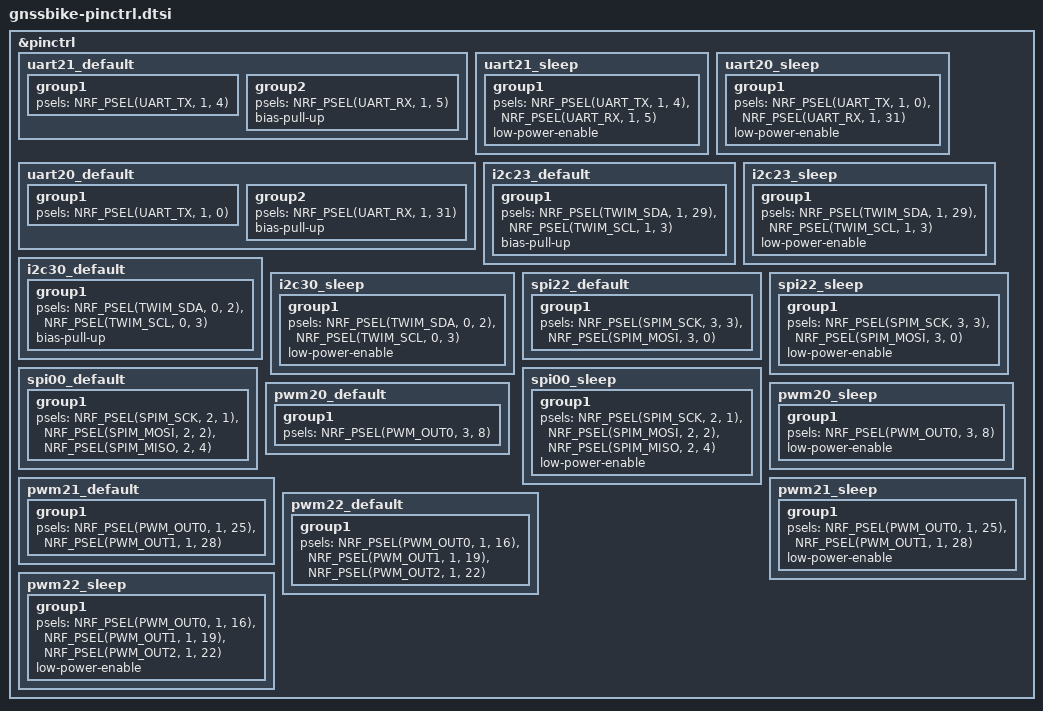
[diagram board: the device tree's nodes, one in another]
/*
 * Pin map of the GNSS Bike Computer board.
 *
 * Two rules of the nRF54LM20A (datasheet 4539_001 v1.0) shape it:
 *
 *   - **Clock pins.** The SCL of a TWIM and the SCK of a SPIM only work on
 *     P0.03, P0.04, P0.06, P0.07, P1.03, P1.04, P1.07, P1.13, P1.14, P1.17,
 *     P1.18, P1.23, P1.24, P2.01, P2.06, P3.03 and P3.04 (table 79). The
 *     data pin of the same peripheral sits on a neighbouring ball so the
 *     internal delays match. Three of the four buses here need one, and
 *     they take P0.03, P1.03, P2.01 and P3.03; the rest are left free so a
 *     revision has somewhere to put another bus.
 *   - **NFC pads.** P1.01 (NFC1) and P1.02 (NFC2) leave reset as antenna
 *     pins with the GPIO function off (table 78, NFCT PADCONFIG). Nothing
 *     here uses them, so an NFC antenna stays possible on a later revision.
 *
 * P1.20 and P1.21 carry the 32,768 kHz crystal and are not available.
 *
 * The serial blocks follow the power domains of the part: `spi00` on port
 * P2, blocks 20 to 24 on P1 and P3, block 30 on P0.
 */

&pinctrl {
	/* ---- GNSS: u-blox MAX-F10S through the TXU0204 level shifter ---- */
	uart21_default: uart21_default {
		group1 {
			psels = <NRF_PSEL(UART_TX, 1, 4)>;
		};
		group2 {
			psels = <NRF_PSEL(UART_RX, 1, 5)>;
			bias-pull-up;
		};
	};

	uart21_sleep: uart21_sleep {
		group1 {
			psels = <NRF_PSEL(UART_TX, 1, 4)>,
				<NRF_PSEL(UART_RX, 1, 5)>;
			low-power-enable;
		};
	};

	/*
	 * ---- Console on test pads; no connector on the case ----
	 *
	 * On block 20 and not 30: the serial blocks of this part hold one
	 * peripheral each, and block 30 is the I2C of the power path. The
	 * pin plan of `docs/14` had a console on `uart30` beside an
	 * `i2c30`, which the silicon refuses.
	 */
	uart20_default: uart20_default {
		group1 {
			psels = <NRF_PSEL(UART_TX, 1, 0)>;
		};
		group2 {
			psels = <NRF_PSEL(UART_RX, 1, 31)>;
			bias-pull-up;
		};
	};

	uart20_sleep: uart20_sleep {
		group1 {
			psels = <NRF_PSEL(UART_TX, 1, 0)>,
				<NRF_PSEL(UART_RX, 1, 31)>;
			low-power-enable;
		};
	};

	/* ---- Sensors: BMP585, BMI270, MMC5633NJL, OPT3001 ---- */
	i2c23_default: i2c23_default {
		group1 {
			psels = <NRF_PSEL(TWIM_SDA, 1, 29)>,
				<NRF_PSEL(TWIM_SCL, 1, 3)>;
			bias-pull-up;
		};
	};

	i2c23_sleep: i2c23_sleep {
		group1 {
			psels = <NRF_PSEL(TWIM_SDA, 1, 29)>,
				<NRF_PSEL(TWIM_SCL, 1, 3)>;
			low-power-enable;
		};
	};

	/* ---- Energy: nPM1300, MAX17262, AEM10900 ---- */
	i2c30_default: i2c30_default {
		group1 {
			psels = <NRF_PSEL(TWIM_SDA, 0, 2)>,
				<NRF_PSEL(TWIM_SCL, 0, 3)>;
			bias-pull-up;
		};
	};

	i2c30_sleep: i2c30_sleep {
		group1 {
			psels = <NRF_PSEL(TWIM_SDA, 0, 2)>,
				<NRF_PSEL(TWIM_SCL, 0, 3)>;
			low-power-enable;
		};
	};

	/* ---- Display: the panel only listens, so there is no MISO ---- */
	spi22_default: spi22_default {
		group1 {
			psels = <NRF_PSEL(SPIM_SCK, 3, 3)>,
				<NRF_PSEL(SPIM_MOSI, 3, 0)>;
		};
	};

	spi22_sleep: spi22_sleep {
		group1 {
			psels = <NRF_PSEL(SPIM_SCK, 3, 3)>,
				<NRF_PSEL(SPIM_MOSI, 3, 0)>;
			low-power-enable;
		};
	};

	/* ---- Storage: NOR flash, and the microSD of the prototype ---- */
	spi00_default: spi00_default {
		group1 {
			psels = <NRF_PSEL(SPIM_SCK, 2, 1)>,
				<NRF_PSEL(SPIM_MOSI, 2, 2)>,
				<NRF_PSEL(SPIM_MISO, 2, 4)>;
		};
	};

	spi00_sleep: spi00_sleep {
		group1 {
			psels = <NRF_PSEL(SPIM_SCK, 2, 1)>,
				<NRF_PSEL(SPIM_MOSI, 2, 2)>,
				<NRF_PSEL(SPIM_MISO, 2, 4)>;
			low-power-enable;
		};
	};

	/* ---- Front light of the display ---- */
	pwm20_default: pwm20_default {
		group1 {
			psels = <NRF_PSEL(PWM_OUT0, 3, 8)>;
		};
	};

	pwm20_sleep: pwm20_sleep {
		group1 {
			psels = <NRF_PSEL(PWM_OUT0, 3, 8)>;
			low-power-enable;
		};
	};

	/* ---- Piezo buzzer, two channels in antiphase ---- */
	pwm21_default: pwm21_default {
		group1 {
			psels = <NRF_PSEL(PWM_OUT0, 1, 25)>,
				<NRF_PSEL(PWM_OUT1, 1, 28)>;
		};
	};

	pwm21_sleep: pwm21_sleep {
		group1 {
			psels = <NRF_PSEL(PWM_OUT0, 1, 25)>,
				<NRF_PSEL(PWM_OUT1, 1, 28)>;
			low-power-enable;
		};
	};

	/* ---- RGB indicator ---- */
	pwm22_default: pwm22_default {
		group1 {
			psels = <NRF_PSEL(PWM_OUT0, 1, 16)>,
				<NRF_PSEL(PWM_OUT1, 1, 19)>,
				<NRF_PSEL(PWM_OUT2, 1, 22)>;
		};
	};

	pwm22_sleep: pwm22_sleep {
		group1 {
			psels = <NRF_PSEL(PWM_OUT0, 1, 16)>,
				<NRF_PSEL(PWM_OUT1, 1, 19)>,
				<NRF_PSEL(PWM_OUT2, 1, 22)>;
			low-power-enable;
		};
	};
};
